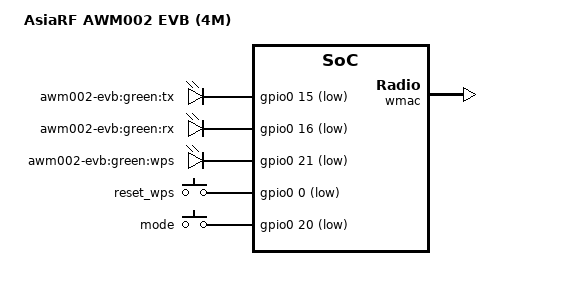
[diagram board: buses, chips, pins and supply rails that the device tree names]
/dts-v1/;

#include "AWM002-4M.dtsi"

#include <dt-bindings/gpio/gpio.h>
#include <dt-bindings/input/input.h>

/ {
	model = "AsiaRF AWM002 EVB (4M)";

	gpio-leds {
		compatible = "gpio-leds";

		tx {
			label = "awm002-evb:green:tx";
			gpios = <&gpio0 15 GPIO_ACTIVE_LOW>;
		};

		rx {
			label = "awm002-evb:green:rx";
			gpios = <&gpio0 16 GPIO_ACTIVE_LOW>;
		};

		wps {
			label = "awm002-evb:green:wps";
			gpios = <&gpio0 21 GPIO_ACTIVE_LOW>;
		};
	};

	gpio-keys-polled {
		compatible = "gpio-keys-polled";
		#address-cells = <1>;
		#size-cells = <0>;
		poll-interval = <20>;

		reset_wps {
			label = "reset_wps";
			gpios = <&gpio0 0 GPIO_ACTIVE_LOW>;
			linux,code = <KEY_RESTART>;
		};

		mode {
			label = "mode";
			gpios = <&gpio0 20 GPIO_ACTIVE_LOW>;
			linux,code = <BTN_0>;
		};
	};
};

&ethernet {
	mtd-mac-address = <&factory 0x28>;
};

&wmac {
	ralink,mtd-eeprom = <&factory 0>;
};
